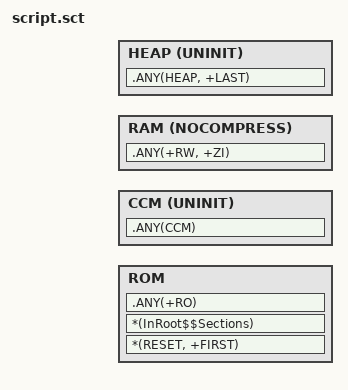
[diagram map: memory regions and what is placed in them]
#! armcc -E
#include "startup.h"

/*******************************************************************************
@file     stm32f4xx.sct
@author   Rajmund Szymanski
@date     16.02.2016
@brief    Scatter file for STM32F407VG device with 1024KB FLASH and 192KB RAM
*******************************************************************************/

FLASH __rom_start __rom_size
{
	ROM +0
	{
		*(RESET, +FIRST)
		*(InRoot$$Sections)
		.ANY(+RO)
	}

	CCM __ccm_start UNINIT __ccm_size
	{
		.ANY(CCM)
	}

	RAM (__ram_start + proc_stack) NOCOMPRESS (__ram_size - proc_stack - main_stack)
	{
		.ANY(+RW, +ZI)
	}

	HEAP ALIGNEXPR(+0, 8) UNINIT
	{
		.ANY(HEAP, +LAST)
	}
}
